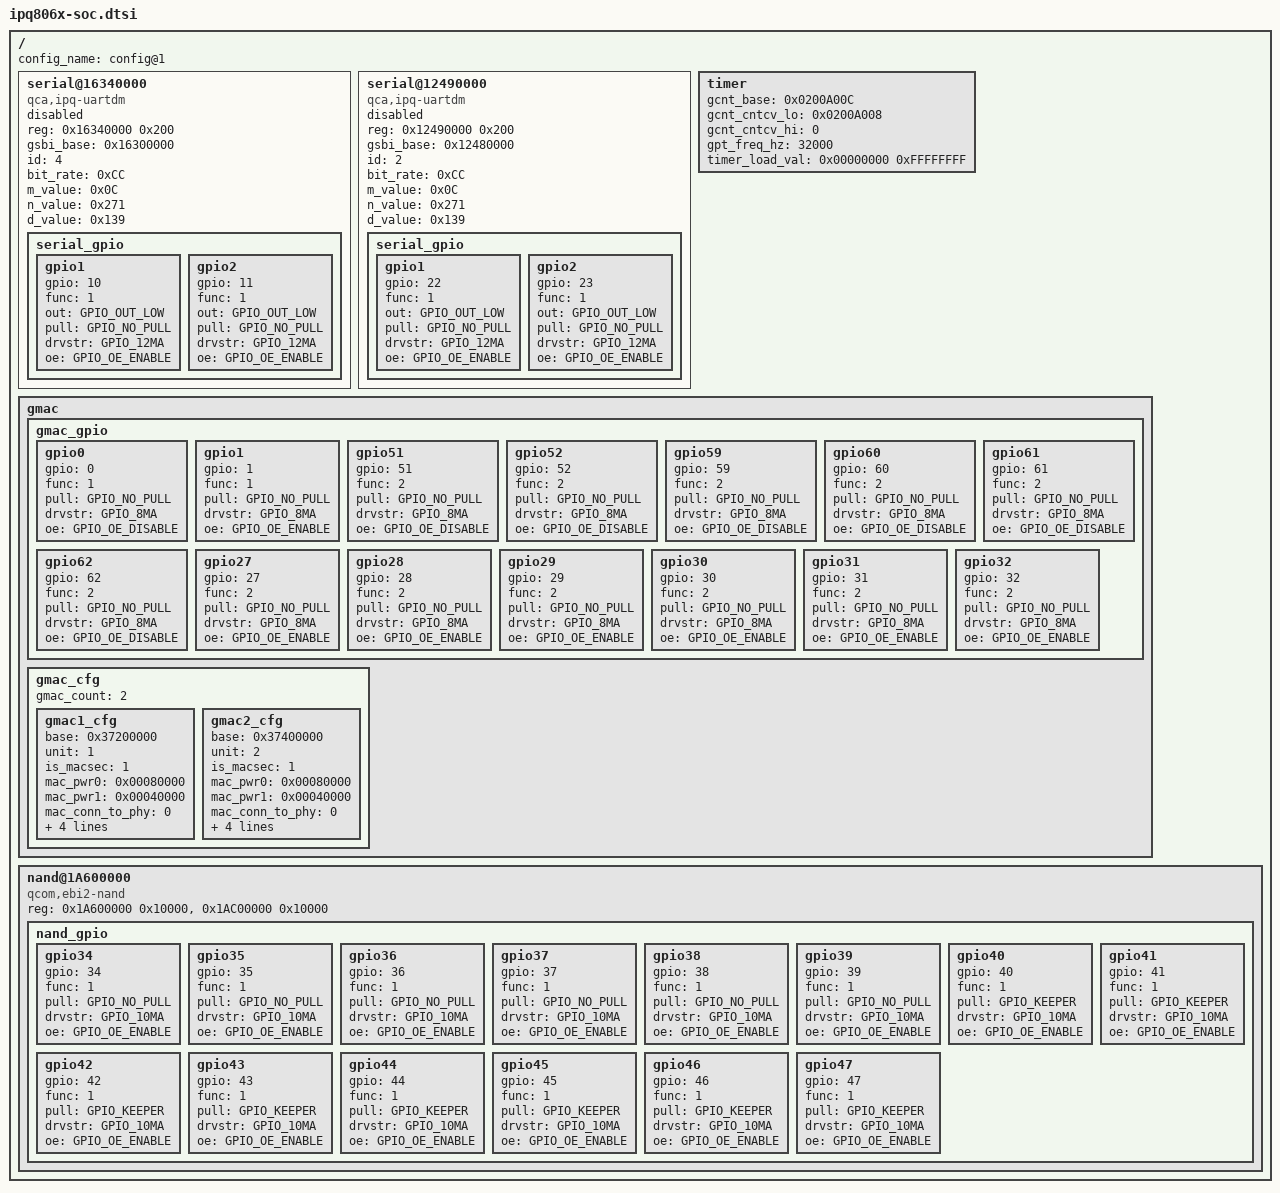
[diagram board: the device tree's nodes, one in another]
/*
 * Copyright (c) 2016, The Linux Foundation. All rights reserved.
 *
 * This program is free software; you can redistribute it and/or modify
 * it under the terms of the GNU General Public License version 2 and
 * only version 2 as published by the Free Software Foundation.
 *
 * This program is distributed in the hope that it will be useful,
 * but WITHOUT ANY WARRANTY; without even the implied warranty of
 * MERCHANTABILITY or FITNESS FOR A PARTICULAR PURPOSE.  See the
 * GNU General Public License for more details.
 */

#include "skeleton.dtsi"
#include <dt-bindings/qcom/gpio-ipq806x.h>

/ {
	config_name = "config@1";

	serial@16340000 {
		status = "disabled";
		compatible = "qca,ipq-uartdm";
		reg = <0x16340000 0x200>;
		gsbi_base = <0x16300000>;
		id = <4>;
		bit_rate = <0xCC>;
		m_value = <0x0C>;
		n_value = <0x271>;
		d_value = <0x139>;

		serial_gpio {
			gpio1 {
				gpio = <10>;
				func = <1>;
				out = <GPIO_OUT_LOW>;
				pull = <GPIO_NO_PULL>;
				drvstr = <GPIO_12MA>;
				oe = <GPIO_OE_ENABLE>;
			};

			gpio2 {
				gpio = <11>;
				func = <1>;
				out = <GPIO_OUT_LOW>;
				pull = <GPIO_NO_PULL>;
				drvstr = <GPIO_12MA>;
				oe = <GPIO_OE_ENABLE>;
			};

		};

	};

	serial@12490000 {
		status = "disabled";
		compatible = "qca,ipq-uartdm";
		reg = <0x12490000 0x200>;
		gsbi_base = <0x12480000>;
		id = <2>;
		bit_rate = <0xCC>;
		m_value = <0x0C>;
		n_value = <0x271>;
		d_value = <0x139>;

		serial_gpio {
			gpio1 {
				gpio = <22>;
				func = <1>;
				out = <GPIO_OUT_LOW>;
				pull = <GPIO_NO_PULL>;
				drvstr = <GPIO_12MA>;
				oe = <GPIO_OE_ENABLE>;
			};

			gpio2 {
				gpio = <23>;
				func = <1>;
				out = <GPIO_OUT_LOW>;
				pull = <GPIO_NO_PULL>;
				drvstr = <GPIO_12MA>;
				oe = <GPIO_OE_ENABLE>;
			};
		};
	};

	timer {
		gcnt_base = <0x0200A00C>;
		gcnt_cntcv_lo = <0x0200A008>;
		gcnt_cntcv_hi = <0>;
		gpt_freq_hz = <32000>;
		timer_load_val = <0x00000000 0xFFFFFFFF>;
	};

	gmac {
		gmac_gpio {
			gpio0 {
				gpio = <0>;
				func = <1>;
				pull = <GPIO_NO_PULL>;
				drvstr = <GPIO_8MA>;
				oe = <GPIO_OE_DISABLE>;
			};

			gpio1 {
				gpio = <1>;
				func = <1>;
				pull = <GPIO_NO_PULL>;
				drvstr = <GPIO_8MA>;
				oe = <GPIO_OE_ENABLE>;
			};

			gpio51 {
				gpio = <51>;
				func = <2>;
				pull = <GPIO_NO_PULL>;
				drvstr = <GPIO_8MA>;
				oe = <GPIO_OE_DISABLE>;
			};

			gpio52 {
				gpio = <52>;
				func = <2>;
				pull = <GPIO_NO_PULL>;
				drvstr = <GPIO_8MA>;
				oe = <GPIO_OE_DISABLE>;
			};

			gpio59 {
				gpio = <59>;
				func = <2>;
				pull = <GPIO_NO_PULL>;
				drvstr = <GPIO_8MA>;
				oe = <GPIO_OE_DISABLE>;
			};

			gpio60 {
				gpio = <60>;
				func = <2>;
				pull = <GPIO_NO_PULL>;
				drvstr = <GPIO_8MA>;
				oe = <GPIO_OE_DISABLE>;
			};

			gpio61 {
				gpio = <61>;
				func = <2>;
				pull = <GPIO_NO_PULL>;
				drvstr = <GPIO_8MA>;
				oe = <GPIO_OE_DISABLE>;
			};

			gpio62 {
				gpio = <62>;
				func = <2>;
				pull = <GPIO_NO_PULL>;
				drvstr = <GPIO_8MA>;
				oe = <GPIO_OE_DISABLE>;
			};

			gpio27 {
				gpio = <27>;
				func = <2>;
				pull = <GPIO_NO_PULL>;
				drvstr = <GPIO_8MA>;
				oe = <GPIO_OE_ENABLE>;
			};

			gpio28 {
				gpio = <28>;
				func = <2>;
				pull = <GPIO_NO_PULL>;
				drvstr = <GPIO_8MA>;
				oe = <GPIO_OE_ENABLE>;
			};

			gpio29 {
				gpio = <29>;
				func = <2>;
				pull = <GPIO_NO_PULL>;
				drvstr = <GPIO_8MA>;
				oe = <GPIO_OE_ENABLE>;
			};

			gpio30 {
				gpio = <30>;
				func = <2>;
				pull = <GPIO_NO_PULL>;
				drvstr = <GPIO_8MA>;
				oe = <GPIO_OE_ENABLE>;
			};

			gpio31 {
				gpio = <31>;
				func = <2>;
				pull = <GPIO_NO_PULL>;
				drvstr = <GPIO_8MA>;
				oe = <GPIO_OE_ENABLE>;
			};

			gpio32 {
				gpio = <32>;
				func = <2>;
				pull = <GPIO_NO_PULL>;
				drvstr = <GPIO_8MA>;
				oe = <GPIO_OE_ENABLE>;
			};
		};

		gmac_cfg {
			gmac_count = <2>;

			gmac1_cfg {
				base = <0x37200000>;
				unit = <1>;
				is_macsec = <1>;
				mac_pwr0 = <0x00080000>;
				mac_pwr1 = <0x00040000>;
				mac_conn_to_phy = <0>;
				phy_interface_type = <7>;
				phy_address_count = <1>;
				phy_address = <4>;
				phy_name = "IPQ MDIO1";
			};

			gmac2_cfg {
				base = <0x37400000>;
				unit = <2>;
				is_macsec = <1>;
				mac_pwr0 = <0x00080000>;
				mac_pwr1 = <0x00040000>;
				mac_conn_to_phy = <0>;
				phy_interface_type = <2>;
				phy_address_count = <4>;
				phy_address = <0 1 2 3>;
				phy_name = "IPQ MDIO2";
			};
		};
	};

	nand@1A600000 {
		#address-cells = <1>;
		#size-cells = <0>;
		compatible = "qcom,ebi2-nand";
		reg = <0x1A600000 0x10000>,
			<0x1AC00000 0x10000>;
		reg-names = "EBI2_CR", "EBI2ND";
		status = "ok";
		nand_gpio {
			gpio34 {
				gpio = <34>;
				func = <1>;
				pull = <GPIO_NO_PULL>;
				drvstr = <GPIO_10MA>;
				oe = <GPIO_OE_ENABLE>;
			};

			gpio35 {
				gpio = <35>;
				func = <1>;
				pull = <GPIO_NO_PULL>;
				drvstr = <GPIO_10MA>;
				oe = <GPIO_OE_ENABLE>;
			};

			gpio36 {
				gpio = <36>;
				func = <1>;
				pull = <GPIO_NO_PULL>;
				drvstr = <GPIO_10MA>;
				oe = <GPIO_OE_ENABLE>;
			};

			gpio37 {
				gpio = <37>;
				func = <1>;
				pull = <GPIO_NO_PULL>;
				drvstr = <GPIO_10MA>;
				oe = <GPIO_OE_ENABLE>;
			};

			gpio38 {
				gpio = <38>;
				func = <1>;
				pull = <GPIO_NO_PULL>;
				drvstr = <GPIO_10MA>;
				oe = <GPIO_OE_ENABLE>;
			};

			gpio39 {
				gpio = <39>;
				func = <1>;
				pull = <GPIO_NO_PULL>;
				drvstr = <GPIO_10MA>;
				oe = <GPIO_OE_ENABLE>;
			};

			gpio40 {
				gpio = <40>;
				func = <1>;
				pull = <GPIO_KEEPER>;
				drvstr = <GPIO_10MA>;
				oe = <GPIO_OE_ENABLE>;
			};

			gpio41 {
				gpio = <41>;
				func = <1>;
				pull = <GPIO_KEEPER>;
				drvstr = <GPIO_10MA>;
				oe = <GPIO_OE_ENABLE>;
			};

			gpio42 {
				gpio = <42>;
				func = <1>;
				pull = <GPIO_KEEPER>;
				drvstr = <GPIO_10MA>;
				oe = <GPIO_OE_ENABLE>;
			};

			gpio43 {
				gpio = <43>;
				func = <1>;
				pull = <GPIO_KEEPER>;
				drvstr = <GPIO_10MA>;
				oe = <GPIO_OE_ENABLE>;
			};

			gpio44 {
				gpio = <44>;
				func = <1>;
				pull = <GPIO_KEEPER>;
				drvstr = <GPIO_10MA>;
				oe = <GPIO_OE_ENABLE>;
			};

			gpio45 {
				gpio = <45>;
				func = <1>;
				pull = <GPIO_KEEPER>;
				drvstr = <GPIO_10MA>;
				oe = <GPIO_OE_ENABLE>;
			};

			gpio46 {
				gpio = <46>;
				func = <1>;
				pull = <GPIO_KEEPER>;
				drvstr = <GPIO_10MA>;
				oe = <GPIO_OE_ENABLE>;
			};

			gpio47 {
				gpio = <47>;
				func = <1>;
				pull = <GPIO_KEEPER>;
				drvstr = <GPIO_10MA>;
				oe = <GPIO_OE_ENABLE>;
			};
		};

	};
};

